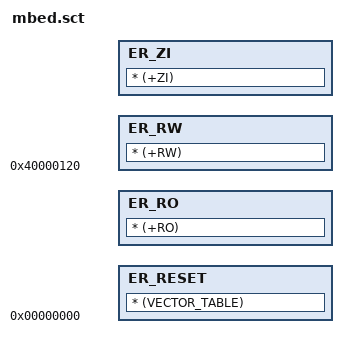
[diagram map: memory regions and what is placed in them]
; Copyright 2008 ARM Limited. All rights reserved.

FLASH_LOAD 0x0 0x00080000
{

  ER_RESET +0
  {
    * (VECTOR_TABLE)
  }

  ER_RO +0
  {
    * (+RO)
  }

  ER_RW 0x40000120
  {    
   * (+RW)
  }

  ER_ZI +0
  {    
   * (+ZI)
  }

}
